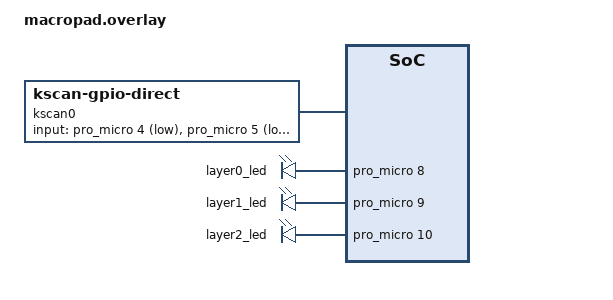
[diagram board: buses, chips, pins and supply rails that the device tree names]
#include <dt-bindings/zmk/matrix_transform.h>

/ {
    chosen {
        zmk,kscan = &kscan0;
        zmk,matrix_transform = &default_transform;
    };

    default_transform: keymap_transform_0 {
        compatible = "zmk,matrix-transform";
        columns = <4>;
        rows = <1>;
        map = <RC(0,0) RC(0,1) RC(0,2) RC(0,3)>;
    };

    kscan0: kscan {
        compatible = "zmk,kscan-gpio-direct";
        input-gpios
            = <&pro_micro 4 (GPIO_ACTIVE_LOW | GPIO_PULL_UP)>
            , <&pro_micro 5 (GPIO_ACTIVE_LOW | GPIO_PULL_UP)>
            , <&pro_micro 6 (GPIO_ACTIVE_LOW | GPIO_PULL_UP)>
            , <&pro_micro 7 (GPIO_ACTIVE_LOW | GPIO_PULL_UP)>
            ;
    };

    layer_leds {
        compatible = "gpio-leds";
        layer0_led: layer0_led { gpios = <&pro_micro 8 GPIO_ACTIVE_HIGH>; };
        layer1_led: layer1_led { gpios = <&pro_micro 9 GPIO_ACTIVE_HIGH>; };
        layer2_led: layer2_led { gpios = <&pro_micro 10 GPIO_ACTIVE_HIGH>; };
    };
};
